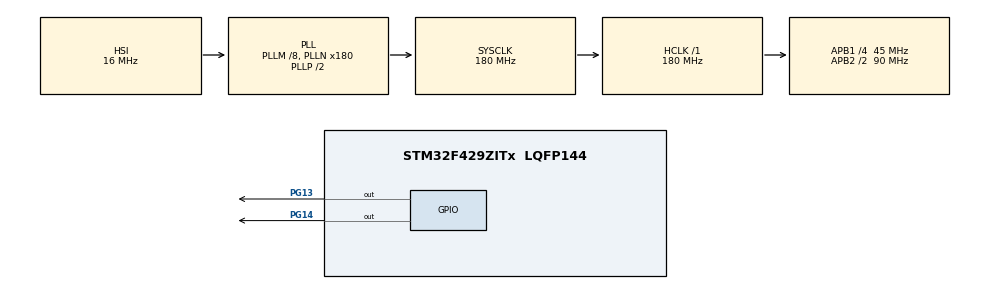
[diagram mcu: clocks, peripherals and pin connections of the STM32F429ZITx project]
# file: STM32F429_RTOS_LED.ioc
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Mcu.Family=STM32F4
RCC.CortexFreq_Value=180000000
FREERTOS.Tasks01=ledTask01,24,128,StartLedTask01,Default,NULL,Dynamic,NULL,NULL;ledTask02,8,128,StartLedTask02,Default,NULL,Dynamic,NULL,NULL
RCC.APB1CLKDivider=RCC_HCLK_DIV4
PG13.Signal=GPIO_Output
RCC.SYSCLKSource=RCC_SYSCLKSOURCE_PLLCLK
ProjectManager.StackSize=0x400
VP_FREERTOS_VS_CMSIS_V2.Mode=CMSIS_V2
PA13.Signal=SYS_JTMS-SWDIO
ProjectManager.TargetToolchain=STM32CubeIDE
RCC.HCLKFreq_Value=180000000
RCC.APB2TimFreq_Value=180000000
RCC.LSE_VALUE=32768
RCC.AHBFreq_Value=180000000
PG14.Signal=GPIO_Output
RCC.HSE_VALUE=25000000
board=custom
RCC.VCOOutputFreq_Value=360000000
RCC.APB2Freq_Value=90000000
PA14.Mode=Serial_Wire
NVIC.TIM2_IRQn=true\:0\:0\:false\:false\:true\:false\:false\:true
PA13.Mode=Serial_Wire
Mcu.Name=STM32F429ZITx
RCC.48MHZClocksFreq_Value=90000000
RCC.SYSCLKFreq_VALUE=180000000
VP_SYS_VS_tim2.Mode=TIM2
Mcu.Package=LQFP144
NVIC.TimeBase=TIM2_IRQn
NVIC.TimeBaseIP=TIM2
PA14.Signal=SYS_JTCK-SWCLK
ProjectManager.HeapSize=0x200
RCC.HSI_VALUE=16000000
NVIC.PriorityGroup=NVIC_PRIORITYGROUP_4
RCC.APB2CLKDivider=RCC_HCLK_DIV2
RCC.PLLM=8
RCC.PLLN=180
RCC.APB1TimFreq_Value=90000000
RCC.APB1Freq_Value=45000000

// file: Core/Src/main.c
/* USER CODE BEGIN Header */
/**
  ******************************************************************************
  * @file           : main.c
  * @brief          : Main program body
  ******************************************************************************
  * @attention
  *
  * <h2><center>&copy; Copyright (c) 2022 STMicroelectronics.
  * All rights reserved.</center></h2>
  *
  * This software component is licensed by ST under BSD 3-Clause license,
  * the "License"; You may not use this file except in compliance with the
  * License. You may obtain a copy of the License at:
  *                        opensource.org/licenses/BSD-3-Clause
  *
  ******************************************************************************
  */
/* USER CODE END Header */
#include "main.h"
#include "cmsis_os.h"

/* Definitions for ledTask01 */
osThreadId_t ledTask01Handle;
const osThreadAttr_t ledTask01_attributes = {
  .name = "ledTask01",
  .stack_size = 128 * 4,
  .priority = (osPriority_t) osPriorityNormal,
};
/* Definitions for ledTask02 */
osThreadId_t ledTask02Handle;
const osThreadAttr_t ledTask02_attributes = {
  .name = "ledTask02",
  .stack_size = 128 * 4,
  .priority = (osPriority_t) osPriorityLow,
};

void SystemClock_Config(void);
static void MX_GPIO_Init(void);
void StartLedTask01(void *argument);
void StartLedTask02(void *argument);

int main(void)
{

  /* MCU Configuration--------------------------------------------------------*/

  /* Reset of all peripherals, Initializes the Flash interface and the Systick. */
  HAL_Init();

  /* Configure the system clock */
  SystemClock_Config();

  /* Initialize all configured peripherals */
  MX_GPIO_Init();

  /* Init scheduler */
  osKernelInitialize();

  /* Create the thread(s) */
  /* creation of ledTask01 */
  ledTask01Handle = osThreadNew(StartLedTask01, NULL, &ledTask01_attributes);

  /* creation of ledTask02 */
  ledTask02Handle = osThreadNew(StartLedTask02, NULL, &ledTask02_attributes);

  /* Start scheduler */
  osKernelStart();

  /* We should never get here as control is now taken by the scheduler */
  /* Infinite loop */
  while (1)
  {

  }
}

void SystemClock_Config(void)
{
  RCC_OscInitTypeDef RCC_OscInitStruct = {0};
  RCC_ClkInitTypeDef RCC_ClkInitStruct = {0};

  /** Configure the main internal regulator output voltage
  */
  __HAL_RCC_PWR_CLK_ENABLE();
  __HAL_PWR_VOLTAGESCALING_CONFIG(PWR_REGULATOR_VOLTAGE_SCALE1);
  /** Initializes the RCC Oscillators according to the specified parameters
  * in the RCC_OscInitTypeDef structure.
  */
  RCC_OscInitStruct.OscillatorType = RCC_OSCILLATORTYPE_HSI;
  RCC_OscInitStruct.HSIState = RCC_HSI_ON;
  RCC_OscInitStruct.HSICalibrationValue = RCC_HSICALIBRATION_DEFAULT;
  RCC_OscInitStruct.PLL.PLLState = RCC_PLL_ON;
  RCC_OscInitStruct.PLL.PLLSource = RCC_PLLSOURCE_HSI;
  RCC_OscInitStruct.PLL.PLLM = 8;
  RCC_OscInitStruct.PLL.PLLN = 180;
  RCC_OscInitStruct.PLL.PLLP = RCC_PLLP_DIV2;
  RCC_OscInitStruct.PLL.PLLQ = 4;
  if (HAL_RCC_OscConfig(&RCC_OscInitStruct) != HAL_OK)
  {
    Error_Handler();
  }
  /** Activate the Over-Drive mode
  */
  if (HAL_PWREx_EnableOverDrive() != HAL_OK)
  {
    Error_Handler();
  }
  /** Initializes the CPU, AHB and APB buses clocks
  */
  RCC_ClkInitStruct.ClockType = RCC_CLOCKTYPE_HCLK|RCC_CLOCKTYPE_SYSCLK
                              |RCC_CLOCKTYPE_PCLK1|RCC_CLOCKTYPE_PCLK2;
  RCC_ClkInitStruct.SYSCLKSource = RCC_SYSCLKSOURCE_PLLCLK;
  RCC_ClkInitStruct.AHBCLKDivider = RCC_SYSCLK_DIV1;
  RCC_ClkInitStruct.APB1CLKDivider = RCC_HCLK_DIV4;
  RCC_ClkInitStruct.APB2CLKDivider = RCC_HCLK_DIV2;

  if (HAL_RCC_ClockConfig(&RCC_ClkInitStruct, FLASH_LATENCY_5) != HAL_OK)
  {
    Error_Handler();
  }
}

static void MX_GPIO_Init(void)
{
  GPIO_InitTypeDef GPIO_InitStruct = {0};

  /* GPIO Ports Clock Enable */
  __HAL_RCC_GPIOA_CLK_ENABLE();
  __HAL_RCC_GPIOG_CLK_ENABLE();

  /*Configure GPIO pin Output Level */
  HAL_GPIO_WritePin(GPIOG, GPIO_PIN_13|GPIO_PIN_14, GPIO_PIN_RESET);

  /*Configure GPIO pins : PG13 PG14 */
  GPIO_InitStruct.Pin = GPIO_PIN_13|GPIO_PIN_14;
  GPIO_InitStruct.Mode = GPIO_MODE_OUTPUT_PP;
  GPIO_InitStruct.Pull = GPIO_NOPULL;
  GPIO_InitStruct.Speed = GPIO_SPEED_FREQ_LOW;
  HAL_GPIO_Init(GPIOG, &GPIO_InitStruct);

}

void StartLedTask01(void *argument)
{
  /* USER CODE BEGIN 5 */
  /* Infinite loop */
  for(;;)
  {
	HAL_GPIO_TogglePin(GPIOG, GPIO_PIN_14);
	osDelay(3000);
  }
  /* USER CODE END 5 */
}

void StartLedTask02(void *argument)
{
  /* USER CODE BEGIN StartLedTask02 */
  /* Infinite loop */
  for(;;)
  {
	HAL_GPIO_TogglePin(GPIOG, GPIO_PIN_13);
    osDelay(1000);
  }
  /* USER CODE END StartLedTask02 */
}

 /**
  * @brief  Period elapsed callback in non blocking mode
  * @note   This function is called  when TIM2 interrupt took place, inside
  * HAL_TIM_IRQHandler(). It makes a direct call to HAL_IncTick() to increment
  * a global variable "uwTick" used as application time base.
  * @param  htim : TIM handle
  * @retval None
  */
void HAL_TIM_PeriodElapsedCallback(TIM_HandleTypeDef *htim)
{
  if (htim->Instance == TIM2) {
    HAL_IncTick();
  }
}

void Error_Handler(void)
{
  __disable_irq();
  while (1)
  {
  }
}

/************************ (C) COPYRIGHT STMicroelectronics *****END OF FILE****/
